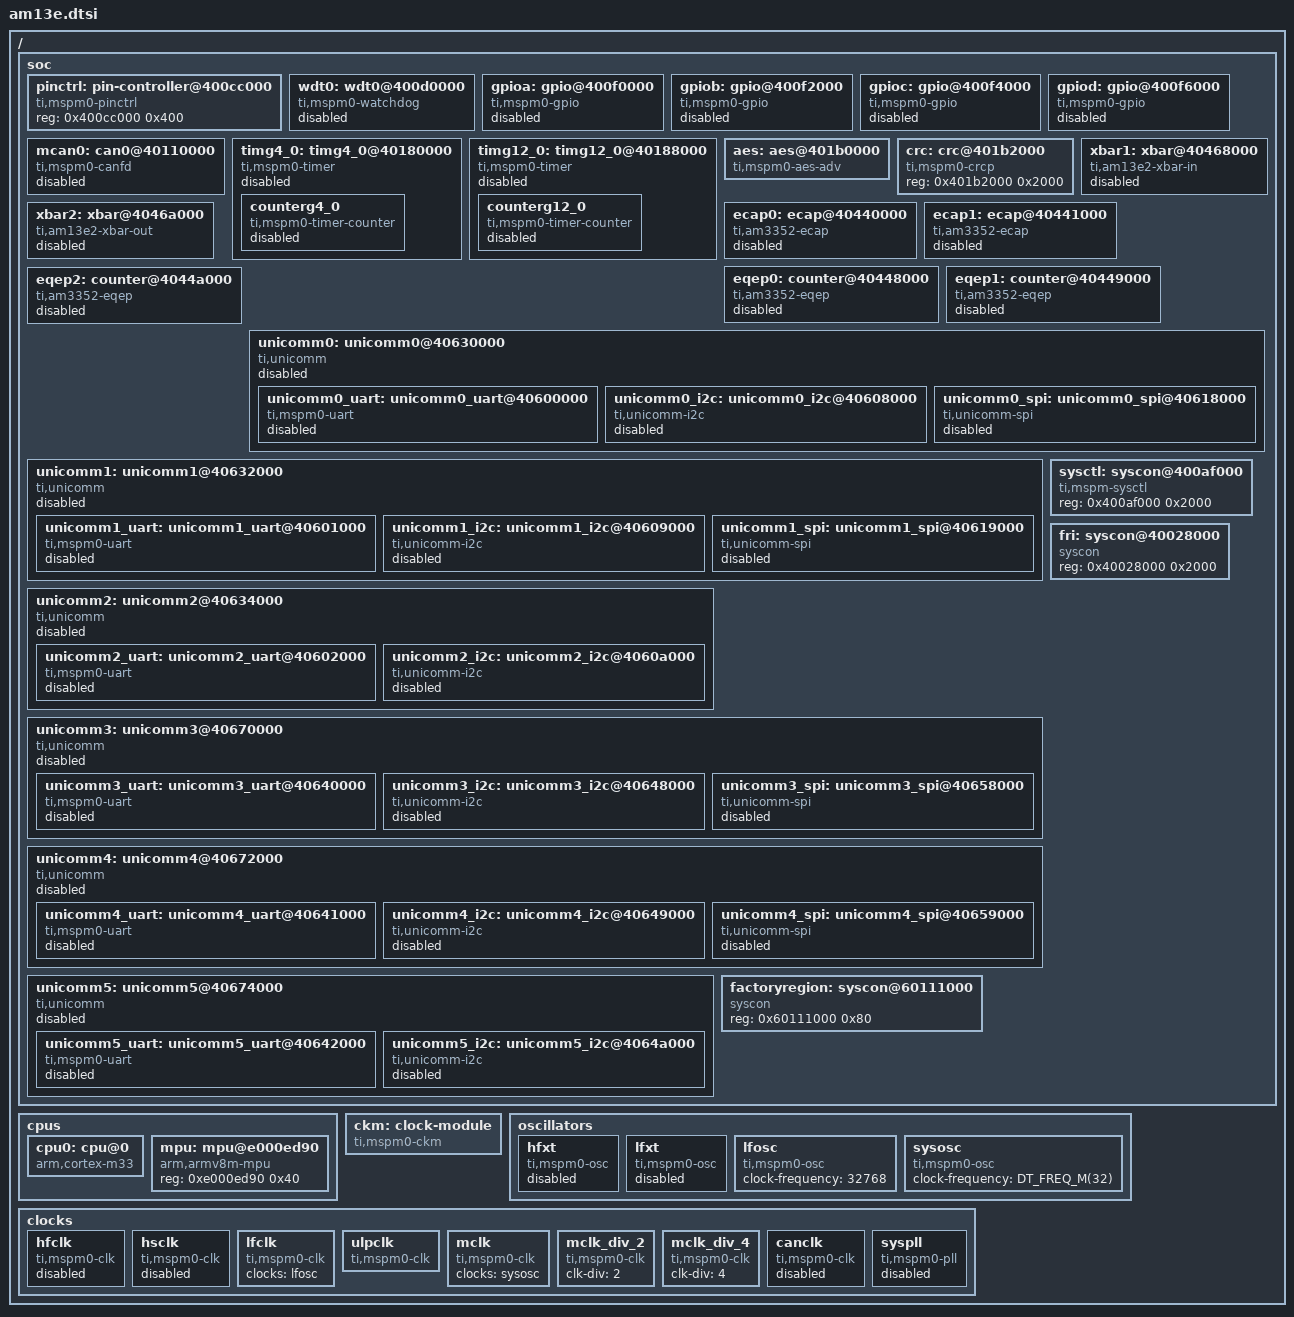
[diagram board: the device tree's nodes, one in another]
/*
 * Copyright (c) 2026 Texas Instruments Incorporated
 *
 * SPDX-License-Identifier: Apache-2.0
 */

#include <arm/armv8-m.dtsi>
#include <mem.h>
#include <freq.h>
#include <zephyr/dt-bindings/clock/mspm0_clock.h>
#include <zephyr/dt-bindings/misc/ti_mspm_sysctl.h>

/ {
	soc {
		pinctrl: pin-controller@400cc000 {
			compatible = "ti,mspm0-pinctrl";
			reg = <0x400cc000 0x400>;
		};

		wdt0: wdt0@400d0000 {
			compatible = "ti,mspm0-watchdog";
			reg = <0x400d0000 0x2000>;
			interrupts = <3 0>;
			clocks = <&ckm MSPM0_CLOCK_LFCLK>;
			ti,watchdog-reset-action = <1>;
			closed-window = <0>;
			status = "disabled";
		};

		gpioa: gpio@400f0000 {
			compatible = "ti,mspm0-gpio";
			reg = <0x400f0000 0x2000>;
			interrupts = <4 0>;
			status = "disabled";
			gpio-controller;
			#gpio-cells = <2>;
		};

		gpiob: gpio@400f2000 {
			compatible = "ti,mspm0-gpio";
			reg = <0x400f2000 0x2000>;
			interrupts = <5 0>;
			status = "disabled";
			gpio-controller;
			#gpio-cells = <2>;
		};

		gpioc: gpio@400f4000 {
			compatible = "ti,mspm0-gpio";
			reg = <0x400f4000 0x2000>;
			interrupts = <6 0>;
			status = "disabled";
			gpio-controller;
			#gpio-cells = <2>;
		};

		gpiod: gpio@400f6000 {
			compatible = "ti,mspm0-gpio";
			reg = <0x400f6000 0x2000>;
			interrupts = <7 0>;
			status = "disabled";
			gpio-controller;
			#gpio-cells = <2>;
			ngpios = <12>;
		};

		mcan0: can0@40110000 {
			compatible = "ti,mspm0-canfd";
			reg = <0x40110000 0x8000>,
			      <0x40117000 0x1000>,
			      <0x40110000 0x400>;
			reg-names = "ti_canfd",
				    "m_can",
				    "message_ram";
			interrupts = <23 0>;
			clocks = <&ckm MSPM0_CLOCK_CANCLK>;
			bosch,mram-cfg = <0x0 20 8 3 3 0 3 3>;
			status = "disabled";
		};

		timg4_0: timg4_0@40180000 {
			compatible = "ti,mspm0-timer";
			reg = <0x40180000 0x2000>;
			clocks = <&ckm MSPM0_CLOCK_MCLK_DIV_2>;
			interrupts = <44 0>;
			ti,clk-prescaler = <255>;
			ti,clk-div = <1>;
			status = "disabled";

			counterg4_0: counterg4_0 {
				compatible = "ti,mspm0-timer-counter";
				resolution = <16>;
				channels = <2>;
				status = "disabled";
			};
		};

		timg12_0: timg12_0@40188000 {
			compatible = "ti,mspm0-timer";
			reg = <0x40188000 0x2000>;
			clocks = <&ckm MSPM0_CLOCK_MCLK_DIV_2>;
			interrupts = <45 0>;
			ti,clk-prescaler = <0>;
			ti,clk-div = <1>;
			status = "disabled";

			counterg12_0: counterg12_0 {
				compatible = "ti,mspm0-timer-counter";
				resolution = <32>;
				channels = <2>;
				status = "disabled";
			};
		};

		aes: aes@401b0000 {
			compatible = "ti,mspm0-aes-adv";
			reg = <0x401b0000 0x2000>;
			interrupts = <43 0>;
		};

		crc: crc@401b2000 {
			compatible = "ti,mspm0-crcp";
			reg = <0x401b2000 0x2000>;
		};

		xbar1: xbar@40468000 {
			compatible = "ti,am13e2-xbar-in";
			reg = <0x40468000 0x1000>;
			ti,pwren = <&sysctl MSPM_SYSCTL_PWREN_MCPERIPH
				    MSPM_SYSCTL_PWREN_XBAR_BIT>;
			#mux-control-cells = <1>;
			#mux-state-cells = <2>;
			status = "disabled";
		};

		xbar2: xbar@4046a000 {
			compatible = "ti,am13e2-xbar-out";
			reg = <0x4046a000 0x1000>;
			ti,pwren = <&sysctl MSPM_SYSCTL_PWREN_MCPERIPH
				    MSPM_SYSCTL_PWREN_XBAR_BIT>;
			#mux-control-cells = <1>;
			#mux-state-cells = <2>;
			status = "disabled";
		};

		ecap0: ecap@40440000 {
			compatible = "ti,am3352-ecap";
			reg = <0x40440000 0x40>;
			clocks = <&ckm MSPM0_CLOCK_MCLK>;
			ti,pwren = <&sysctl MSPM_SYSCTL_PWREN_MCPERIPH
				    MSPM_SYSCTL_PWREN_ECAP0_BIT>;

			#pwm-cells = <3>;
			status = "disabled";
		};

		ecap1: ecap@40441000 {
			compatible = "ti,am3352-ecap";
			reg = <0x40441000 0x40>;
			clocks = <&ckm MSPM0_CLOCK_MCLK>;
			ti,pwren = <&sysctl MSPM_SYSCTL_PWREN_MCPERIPH
				    MSPM_SYSCTL_PWREN_ECAP1_BIT>;

			#pwm-cells = <3>;
			status = "disabled";
		};

		eqep0: counter@40448000 {
			compatible = "ti,am3352-eqep";
			reg = <0x40448000 0x100>;
			interrupts = <31 0>;
			clocks = <&ckm MSPM0_CLOCK_MCLK>;
			ti,pwren = <&sysctl MSPM_SYSCTL_PWREN_MCPERIPH
				    MSPM_SYSCTL_PWREN_EQEP0_BIT>;
			status = "disabled";
		};

		eqep1: counter@40449000 {
			compatible = "ti,am3352-eqep";
			reg = <0x40449000 0x100>;
			interrupts = <32 0>;
			clocks = <&ckm MSPM0_CLOCK_MCLK>;
			ti,pwren = <&sysctl MSPM_SYSCTL_PWREN_MCPERIPH
				    MSPM_SYSCTL_PWREN_EQEP1_BIT>;
			status = "disabled";
		};

		eqep2: counter@4044a000 {
			compatible = "ti,am3352-eqep";
			reg = <0x4044a000 0x100>;
			interrupts = <33 0>;
			clocks = <&ckm MSPM0_CLOCK_MCLK>;
			ti,pwren = <&sysctl MSPM_SYSCTL_PWREN_MCPERIPH
				    MSPM_SYSCTL_PWREN_EQEP2_BIT>;
			status = "disabled";
		};

		unicomm0: unicomm0@40630000 {
			reg = <0x40630000 DT_SIZE_K(8)>;
			compatible = "ti,unicomm";
			interrupts = <34 0>;
			#address-cells = <1>;
			#size-cells = <1>;
			status = "disabled";

			unicomm0_uart: unicomm0_uart@40600000 {
				reg = <0x40600000 DT_SIZE_K(8)>;
				interrupts = <34 0>;
				#address-cells = <1>;
				#size-cells = <1>;
				compatible = "ti,mspm0-uart";
				is-unicomm-uart;
				clocks = <&ckm MSPM0_CLOCK_MCLK_DIV_2>;
				status = "disabled";
			};

			unicomm0_i2c: unicomm0_i2c@40608000 {
				reg = <0x40608000 DT_SIZE_K(4)>, <0x40610000 DT_SIZE_K(4)>;
				reg-names = "controller", "target";
				interrupts = <34 0>;
				compatible = "ti,unicomm-i2c";
				clocks = <&ckm MSPM0_CLOCK_MCLK_DIV_2>;
				#address-cells = <1>;
				#size-cells = <0>;
				status = "disabled";
			};

			unicomm0_spi: unicomm0_spi@40618000 {
				compatible = "ti,unicomm-spi";
				reg = <0x40618000 DT_SIZE_K(8)>;
				#address-cells = <1>;
				#size-cells = <0>;
				interrupts = <34 0>;
				clocks = <&ckm MSPM0_CLOCK_MCLK_DIV_2>;
				status = "disabled";
			};
		};

		unicomm1: unicomm1@40632000 {
			reg = <0x40632000 DT_SIZE_K(8)>;
			compatible = "ti,unicomm";
			interrupts = <35 0>;
			#address-cells = <1>;
			#size-cells = <1>;
			status = "disabled";

			unicomm1_uart: unicomm1_uart@40601000 {
				reg = <0x40601000 DT_SIZE_K(8)>;
				interrupts = <35 0>;
				#address-cells = <1>;
				#size-cells = <1>;
				compatible = "ti,mspm0-uart";
				is-unicomm-uart;
				clocks = <&ckm MSPM0_CLOCK_MCLK_DIV_2>;
				status = "disabled";
			};

			unicomm1_i2c: unicomm1_i2c@40609000 {
				reg = <0x40609000 DT_SIZE_K(4)>, <0x40611000 DT_SIZE_K(4)>;
				reg-names = "controller", "target";
				interrupts = <35 0>;
				compatible = "ti,unicomm-i2c";
				clocks = <&ckm MSPM0_CLOCK_MCLK_DIV_2>;
				#address-cells = <1>;
				#size-cells = <0>;
				status = "disabled";
			};

			unicomm1_spi: unicomm1_spi@40619000 {
				compatible = "ti,unicomm-spi";
				reg = <0x40619000 DT_SIZE_K(8)>;
				#address-cells = <1>;
				#size-cells = <0>;
				interrupts = <35 0>;
				clocks = <&ckm MSPM0_CLOCK_MCLK_DIV_2>;
				status = "disabled";
			};
		};

		unicomm2: unicomm2@40634000 {
			reg = <0x40634000 DT_SIZE_K(8)>;
			compatible = "ti,unicomm";
			interrupts = <36 0>;
			#address-cells = <1>;
			#size-cells = <1>;
			status = "disabled";

			unicomm2_uart: unicomm2_uart@40602000 {
				reg = <0x40602000 DT_SIZE_K(8)>;
				interrupts = <36 0>;
				#address-cells = <1>;
				#size-cells = <1>;
				compatible = "ti,mspm0-uart";
				is-unicomm-uart;
				clocks = <&ckm MSPM0_CLOCK_MCLK_DIV_2>;
				status = "disabled";
			};

			unicomm2_i2c: unicomm2_i2c@4060a000 {
				reg = <0x4060a000 DT_SIZE_K(4)>, <0x40612000 DT_SIZE_K(4)>;
				reg-names = "controller", "target";
				interrupts = <36 0>;
				compatible = "ti,unicomm-i2c";
				unicomm-advanced-i2c;
				clocks = <&ckm MSPM0_CLOCK_MCLK_DIV_2>;
				#address-cells = <1>;
				#size-cells = <0>;
				status = "disabled";
			};
		};

		unicomm3: unicomm3@40670000 {
			reg = <0x40670000 DT_SIZE_K(8)>;
			compatible = "ti,unicomm";
			interrupts = <37 0>;
			#address-cells = <1>;
			#size-cells = <1>;
			status = "disabled";

			unicomm3_uart: unicomm3_uart@40640000 {
				reg = <0x40640000 DT_SIZE_K(8)>;
				interrupts = <37 0>;
				#address-cells = <1>;
				#size-cells = <1>;
				compatible = "ti,mspm0-uart";
				is-unicomm-uart;
				clocks = <&ckm MSPM0_CLOCK_MCLK_DIV_2>;
				status = "disabled";
			};

			unicomm3_i2c: unicomm3_i2c@40648000 {
				reg = <0x40648000 DT_SIZE_K(4)>, <0x40650000 DT_SIZE_K(4)>;
				reg-names = "controller", "target";
				interrupts = <37 0>;
				compatible = "ti,unicomm-i2c";
				clocks = <&ckm MSPM0_CLOCK_MCLK_DIV_2>;
				#address-cells = <1>;
				#size-cells = <0>;
				status = "disabled";
			};

			unicomm3_spi: unicomm3_spi@40658000 {
				compatible = "ti,unicomm-spi";
				reg = <0x40658000 DT_SIZE_K(8)>;
				#address-cells = <1>;
				#size-cells = <0>;
				interrupts = <37 0>;
				clocks = <&ckm MSPM0_CLOCK_MCLK_DIV_2>;
				status = "disabled";
			};
		};

		unicomm4: unicomm4@40672000 {
			reg = <0x40672000 DT_SIZE_K(8)>;
			compatible = "ti,unicomm";
			interrupts = <38 0>;
			#address-cells = <1>;
			#size-cells = <1>;
			status = "disabled";

			unicomm4_uart: unicomm4_uart@40641000 {
				reg = <0x40641000 DT_SIZE_K(8)>;
				interrupts = <38 0>;
				#address-cells = <1>;
				#size-cells = <1>;
				compatible = "ti,mspm0-uart";
				is-unicomm-uart;
				clocks = <&ckm MSPM0_CLOCK_MCLK_DIV_2>;
				status = "disabled";
			};

			unicomm4_i2c: unicomm4_i2c@40649000 {
				reg = <0x40649000 DT_SIZE_K(4)>, <0x40651000 DT_SIZE_K(4)>;
				reg-names = "controller", "target";
				interrupts = <38 0>;
				compatible = "ti,unicomm-i2c";
				clocks = <&ckm MSPM0_CLOCK_MCLK_DIV_2>;
				#address-cells = <1>;
				#size-cells = <0>;
				status = "disabled";
			};

			unicomm4_spi: unicomm4_spi@40659000 {
				compatible = "ti,unicomm-spi";
				reg = <0x40659000 DT_SIZE_K(8)>;
				#address-cells = <1>;
				#size-cells = <0>;
				interrupts = <38 0>;
				clocks = <&ckm MSPM0_CLOCK_MCLK_DIV_2>;
				status = "disabled";
			};
		};

		unicomm5: unicomm5@40674000 {
			reg = <0x40674000 DT_SIZE_K(8)>;
			compatible = "ti,unicomm";
			interrupts = <39 0>;
			#address-cells = <1>;
			#size-cells = <1>;
			status = "disabled";

			unicomm5_uart: unicomm5_uart@40642000 {
				reg = <0x40642000 DT_SIZE_K(8)>;
				interrupts = <39 0>;
				#address-cells = <1>;
				#size-cells = <1>;
				compatible = "ti,mspm0-uart";
				is-unicomm-uart;
				clocks = <&ckm MSPM0_CLOCK_MCLK_DIV_2>;
				status = "disabled";
			};

			unicomm5_i2c: unicomm5_i2c@4064a000 {
				reg = <0x4064a000 DT_SIZE_K(4)>, <0x40652000 DT_SIZE_K(4)>;
				reg-names = "controller", "target";
				interrupts = <39 0>;
				compatible = "ti,unicomm-i2c";
				unicomm-advanced-i2c;
				clocks = <&ckm MSPM0_CLOCK_MCLK_DIV_2>;
				#address-cells = <1>;
				#size-cells = <0>;
				status = "disabled";
			};
		};
	};

	cpus {
		#address-cells = <1>;
		#size-cells = <0>;

		cpu0: cpu@0 {
			device_type = "cpu";
			compatible = "arm,cortex-m33";
			reg = <0>;
			#address-cells = <1>;
			#size-cells = <1>;
			clock-frequency = <DT_FREQ_M(32)>;
		};

		mpu: mpu@e000ed90 {
			compatible = "arm,armv8m-mpu";
			reg = <0xe000ed90 0x40>;
		};
	};

	ckm: clock-module {
		compatible = "ti,mspm0-ckm";
		#clock-cells = <1>;
		sysctl = <&sysctl>;
		factoryregion = <&factoryregion>;
		fri = <&fri>;
	};

	oscillators: oscillators {
		hfxt: hfxt {
			#clock-cells = <0>;
			compatible = "ti,mspm0-osc";
			status = "disabled";
		};

		lfxt: lfxt {
			#clock-cells = <0>;
			compatible = "ti,mspm0-osc";
			status = "disabled";
		};

		lfosc: lfosc {
			#clock-cells = <0>;
			compatible = "ti,mspm0-osc";
			clock-frequency = <32768>;
		};

		sysosc: sysosc {
			#clock-cells = <0>;
			compatible = "ti,mspm0-osc";
			clock-frequency = <DT_FREQ_M(32)>;
		};
	};

	clocks: clocks {
		hfclk: hfclk {
			#clock-cells = <0>;
			compatible = "ti,mspm0-clk";
			status = "disabled";
		};

		hsclk: hsclk {
			#clock-cells = <0>;
			compatible = "ti,mspm0-clk";
			status = "disabled";
		};

		lfclk: lfclk {
			#clock-cells = <0>;
			compatible = "ti,mspm0-clk";
			clocks = <&lfosc>;
		};

		ulpclk: ulpclk {
			#clock-cells = <0>;
			compatible = "ti,mspm0-clk";
		};

		mclk: mclk {
			#clock-cells = <0>;
			compatible = "ti,mspm0-clk";
			clocks = <&sysosc>;
		};

		mclk_div_2: mclk_div_2 {
			#clock-cells = <0>;
			compatible = "ti,mspm0-clk";
			clk-div = <2>;
		};

		mclk_div_4: mclk_div_4 {
			#clock-cells = <0>;
			compatible = "ti,mspm0-clk";
			clk-div = <4>;
		};

		canclk: canclk {
			#clock-cells = <0>;
			compatible = "ti,mspm0-clk";
			status = "disabled";
		};

		syspll: syspll {
			compatible = "ti,mspm0-pll";
			clocks = <&sysosc>;
			p-div = <2>;
			q-div = <25>;
			clk1-div = <2>;
			clk0-div = <2>;
			#clock-cells = <0>;
			status = "disabled";
		};
	};

	soc {
		sysctl: syscon@400af000 {
			compatible = "ti,mspm-sysctl", "syscon";
			reg = <0x400af000 0x2000>;
			#pwren-cells = <2>;
			status = "okay";
		};

		factoryregion: syscon@60111000 {
			compatible = "syscon";
			reg = <0x60111000 0x80>;
		};

		fri: syscon@40028000 {
			compatible = "syscon";
			reg = <0x40028000 0x2000>;
		};
	};
};
